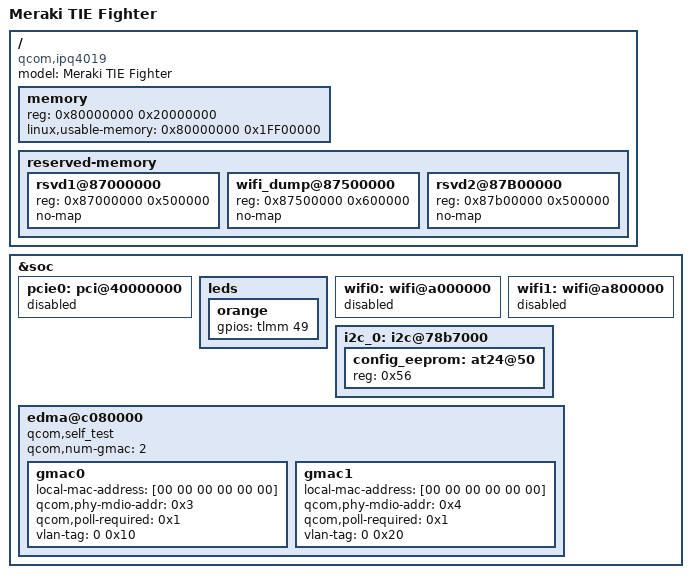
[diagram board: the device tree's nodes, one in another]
#include "wired-arm-qca.dtsi"

/ {
	model = "Meraki TIE Fighter";
	compatible = "qcom,ipq4019","meraki,tiefighter";
	memory {
		reg = <0x80000000 0x20000000>; /* 512 MiB */
		linux,usable-memory = <0x80000000 0x1FF00000>;
	};

	reserved-memory {
		#address-cells = <0x1>;
		#size-cells = <0x1>;
		ranges;

		rsvd1@87000000 {
			reg = <0x87000000 0x500000>;
			no-map;
		};

		wifi_dump@87500000 {
			reg = <0x87500000 0x600000>;
			no-map;
		};

		rsvd2@87B00000 {
			reg = <0x87b00000 0x500000>;
			no-map;
		};
	};

};

&soc {
	pcie0: pci@40000000 {
		status = "disabled";
	};


	leds {
		orange {
			gpios = <&tlmm 49 GPIO_ACTIVE_HIGH>;
		};
	};

	wifi0: wifi@a000000 {
		status = "disabled";
	};

	wifi1: wifi@a800000 {
		status = "disabled";
	};

        i2c_0: i2c@78b7000 { /* BLSP1 QUP2 */
		config_eeprom: at24@50 {
			reg = <0x56>;
		};
	};

	edma@c080000 {
		qcom,self_test;
		qcom,num-gmac = <2>;
		gmac0 {
			local-mac-address = [00 00 00 00 00 00];
			qcom,phy-mdio-addr = <0x3>;
			qcom,poll-required = <0x1>;
			vlan-tag = <0 0x10>;
		};

		gmac1 {
			local-mac-address = [00 00 00 00 00 00];
			qcom,phy-mdio-addr = <0x4>;
			qcom,poll-required = <0x1>;
			vlan-tag = <0 0x20>;
		};
	};
};
